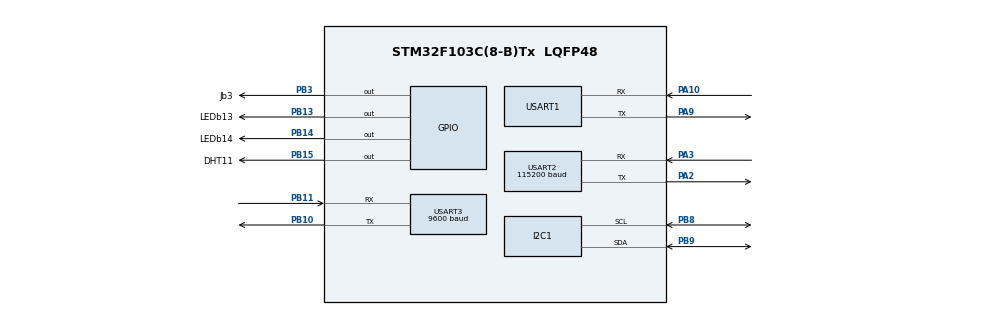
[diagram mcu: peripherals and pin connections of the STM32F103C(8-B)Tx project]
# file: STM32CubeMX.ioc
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Mcu.Family=STM32F1
Mcu.Name=STM32F103C(8-B)Tx
Mcu.Package=LQFP48
NVIC.PriorityGroup=NVIC_PRIORITYGROUP_4
NVIC.TIM2_IRQn=true\:0\:0\:false\:false\:true\:true\:true\:true
NVIC.TIM3_IRQn=true\:0\:0\:false\:false\:true\:true\:true\:true
NVIC.USART2_IRQn=true\:0\:0\:false\:false\:true\:true\:true\:true
NVIC.USART3_IRQn=true\:0\:0\:false\:false\:true\:true\:true\:true
PA10.Mode=Asynchronous
PA10.Signal=USART1_RX
PA13.Mode=Serial_Wire
PA13.Signal=SYS_JTMS-SWDIO
PA14.Mode=Serial_Wire
PA14.Signal=SYS_JTCK-SWCLK
PA2.Mode=Asynchronous
PA2.Signal=USART2_TX
PA3.Mode=Asynchronous
PA3.Signal=USART2_RX
PA9.Mode=Asynchronous
PA9.Signal=USART1_TX
PB10.Mode=Asynchronous
PB10.Signal=USART3_TX
PB11.Mode=Asynchronous
PB11.Signal=USART3_RX
PB13.GPIO_Label=LEDb13
PB13.GPIO_PuPd=GPIO_PULLUP
PB13.Signal=GPIO_Output
PB14.GPIO_Label=LEDb14
PB14.GPIO_PuPd=GPIO_PULLUP
PB14.Signal=GPIO_Output
PB15.GPIO_Label=DHT11
PB15.GPIO_PuPd=GPIO_NOPULL
PB15.PinState=GPIO_PIN_RESET
PB15.Signal=GPIO_Output
PB3.GPIO_Label=Jb3
PB3.GPIO_PuPd=GPIO_PULLUP
PB3.Signal=GPIO_Output
PB8.Mode=I2C
PB8.Signal=I2C1_SCL
PB9.Mode=I2C
PB9.Signal=I2C1_SDA
PD0-OSC_IN.Mode=HSE-External-Oscillator
PD0-OSC_IN.Signal=RCC_OSC_IN
PD1-OSC_OUT.Mode=HSE-External-Oscillator
PD1-OSC_OUT.Signal=RCC_OSC_OUT
ProjectManager.HeapSize=0x200
ProjectManager.StackSize=0x400
ProjectManager.TargetToolchain=MDK-ARM V5.32
RCC.APB1Freq_Value=8000000
RCC.APB2Freq_Value=8000000
RCC.PLLMUL=RCC_PLL_MUL9
RCC.PLLSourceVirtual=RCC_PLLSOURCE_HSE
RCC.USBFreq_Value=72000000
TIM2.Period=100
TIM2.Prescaler=7200-1
TIM3.Period=50
TIM3.Prescaler=7200-1
USART1.VirtualMode=VM_ASYNC
USART2.BaudRate=115200
USART2.VirtualMode=VM_ASYNC
USART3.BaudRate=9600
USART3.VirtualMode=VM_ASYNC
VP_TIM2_VS_ClockSourceINT.Mode=Internal
VP_TIM3_VS_ClockSourceINT.Mode=Internal
board=custom

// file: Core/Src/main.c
/* USER CODE BEGIN Header */
/**
 ******************************************************************************
 * @file           : main.c
 * @brief          : Main program body
 ******************************************************************************
 * @attention
 *
 * Copyright (c) 2024 STMicroelectronics.
 * All rights reserved.
 *
 * This software is licensed under terms that can be found in the LICENSE file
 * in the root directory of this software component.
 * If no LICENSE file comes with this software, it is provided AS-IS.
 *
 ******************************************************************************
 */
/* USER CODE END Header */
#include "main.h"
#include "i2c.h"
#include "tim.h"
#include "usart.h"
#include "gpio.h"

/* USER CODE BEGIN Includes */
#include "main_program.h"
/* USER CODE END Includes */

void SystemClock_Config(void);

int main(void)
{

  /* MCU Configuration--------------------------------------------------------*/

  /* Reset of all peripherals, Initializes the Flash interface and the Systick. */
  HAL_Init();

  /* Configure the system clock */
  SystemClock_Config();

  /* Initialize all configured peripherals */
  MX_GPIO_Init();
  MX_I2C1_Init();
  MX_TIM2_Init();
  MX_USART1_UART_Init();
  MX_USART2_UART_Init();
  MX_TIM3_Init();
  MX_USART3_UART_Init();
  /* USER CODE BEGIN 2 */
  user_init_program();
  /* USER CODE END 2 */

  /* Infinite loop */
  while (1)
  {

    /* USER CODE BEGIN 3 */
    user_main_program();
  }
  /* USER CODE END 3 */
}

void SystemClock_Config(void)
{
  RCC_OscInitTypeDef RCC_OscInitStruct = {0};
  RCC_ClkInitTypeDef RCC_ClkInitStruct = {0};

  /** Initializes the RCC Oscillators according to the specified parameters
  * in the RCC_OscInitTypeDef structure.
  */
  RCC_OscInitStruct.OscillatorType = RCC_OSCILLATORTYPE_HSI;
  RCC_OscInitStruct.HSIState = RCC_HSI_ON;
  RCC_OscInitStruct.HSICalibrationValue = RCC_HSICALIBRATION_DEFAULT;
  RCC_OscInitStruct.PLL.PLLState = RCC_PLL_NONE;
  if (HAL_RCC_OscConfig(&RCC_OscInitStruct) != HAL_OK)
  {
    Error_Handler();
  }

  /** Initializes the CPU, AHB and APB buses clocks
  */
  RCC_ClkInitStruct.ClockType = RCC_CLOCKTYPE_HCLK|RCC_CLOCKTYPE_SYSCLK
                              |RCC_CLOCKTYPE_PCLK1|RCC_CLOCKTYPE_PCLK2;
  RCC_ClkInitStruct.SYSCLKSource = RCC_SYSCLKSOURCE_HSI;
  RCC_ClkInitStruct.AHBCLKDivider = RCC_SYSCLK_DIV1;
  RCC_ClkInitStruct.APB1CLKDivider = RCC_HCLK_DIV1;
  RCC_ClkInitStruct.APB2CLKDivider = RCC_HCLK_DIV1;

  if (HAL_RCC_ClockConfig(&RCC_ClkInitStruct, FLASH_LATENCY_0) != HAL_OK)
  {
    Error_Handler();
  }
}

void Error_Handler(void)
{
  __disable_irq();
  while (1)
  {
  }
}
